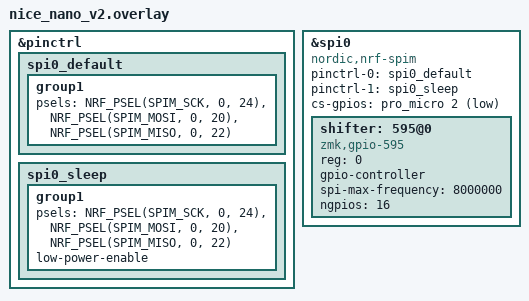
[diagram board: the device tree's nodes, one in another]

/**
 * Generated by Shield Wizard for ZMK
 * Applies to shield "osprey_68" with board "nice_nano_v2" only
 */

//
// ======== spi0 ========
//

// pin control for spi0
// - SCK on D5
// - MOSI on D3
// - MISO on D4
&pinctrl {
    /* configuration for spi0 device, default state */
    spi0_default: spi0_default {
        group1 {
            psels = <NRF_PSEL(SPIM_SCK, 0, 24)>,
                    <NRF_PSEL(SPIM_MOSI, 0, 20)>,
                    <NRF_PSEL(SPIM_MISO, 0, 22)>;
        };
    };
    /* configuration for spi0 device, sleep state */
    spi0_sleep: spi0_sleep {
        group1 {
            psels = <NRF_PSEL(SPIM_SCK, 0, 24)>,
                    <NRF_PSEL(SPIM_MOSI, 0, 20)>,
                    <NRF_PSEL(SPIM_MISO, 0, 22)>;
            low-power-enable;
        };
    };
};
&spi0 {
  compatible = "nordic,nrf-spim";
  status = "okay";
  pinctrl-0 = <&spi0_default>;
  pinctrl-1 = <&spi0_sleep>;
  pinctrl-names = "default", "sleep";
};

// devices on spi0

// CS pins for devices on spi0
&spi0 {
    cs-gpios = <&pro_micro 2 GPIO_ACTIVE_LOW>;
};

&spi0 {
    shifter: 595@0 {
        compatible = "zmk,gpio-595";
        reg = <0>;
        status = "okay";
        gpio-controller;
        spi-max-frequency = <8000000>;
        #gpio-cells = <2>;
        ngpios = <16>;
    };
};
